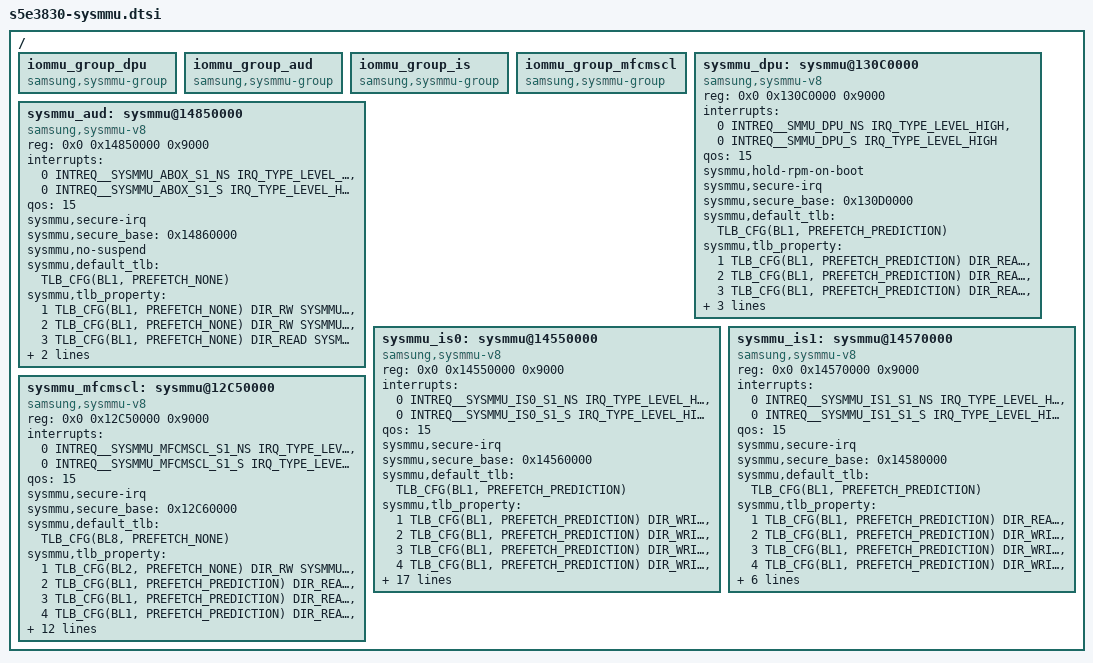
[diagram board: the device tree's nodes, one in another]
/*
 * SAMSUNG S5E3830 SoC device tree source
 *
 * Copyright (c) 2022 Samsung Electronics Co., Ltd.
 *             http://www.samsung.com
 *
 * SAMSUNG S5E3830 SoC device nodes are listed in this file.
 * S5E3830 based board files can include this file and provide
 * values for board specfic bindings.
 *
 * This program is free software; you can redistribute it and/or modify
 * it under the terms of the GNU General Public License version 2 as
 * published by the Free Software Foundation.
 */

#include <dt-bindings/interrupt-controller/arm-gic.h>
#include <dt-bindings/soc/samsung,sysmmu-v8.h>

/ {
	iommu_group_dpu: iommu_group_dpu {
		compatible = "samsung,sysmmu-group";
	};

	iommu_group_aud: iommu_group_aud {
		compatible = "samsung,sysmmu-group";
	};

	iommu_group_is: iommu_group_is {
		compatible = "samsung,sysmmu-group";
	};

	iommu_group_mfcmscl: iommu_group_mfcmscl {
		compatible = "samsung,sysmmu-group";
	};

	sysmmu_dpu: sysmmu@130C0000 {
		compatible = "samsung,sysmmu-v8";
		reg = <0x0 0x130C0000 0x9000>;
		interrupts = <0 INTREQ__SMMU_DPU_NS IRQ_TYPE_LEVEL_HIGH>,
			     <0 INTREQ__SMMU_DPU_S  IRQ_TYPE_LEVEL_HIGH>;
		qos = <15>;

		sysmmu,hold-rpm-on-boot;
		sysmmu,secure-irq;
		sysmmu,secure_base = <0x130D0000>;
		sysmmu,default_tlb = <TLB_CFG(BL1, PREFETCH_PREDICTION)>;
		sysmmu,tlb_property =
			<1 TLB_CFG(BL1, PREFETCH_PREDICTION) DIR_READ SYSMMU_ID_MASK(0x2, 0xF)>,
			<2 TLB_CFG(BL1, PREFETCH_PREDICTION) DIR_READ SYSMMU_ID_MASK(0x4, 0xF)>,
			<3 TLB_CFG(BL1, PREFETCH_PREDICTION) DIR_READ SYSMMU_ID_MASK(0x6, 0xF)>,
			<4 TLB_CFG(BL1, PREFETCH_PREDICTION) DIR_READ SYSMMU_ID_MASK(0x8, 0xF)>;
		port-name = "DPU";
		#iommu-cells = <0>;
		power-domains = <&pd_dpu>;
	};

	sysmmu_aud: sysmmu@14850000 {
		compatible = "samsung,sysmmu-v8";
		reg = <0x0 0x14850000 0x9000>;
		interrupts = <0 INTREQ__SYSMMU_ABOX_S1_NS IRQ_TYPE_LEVEL_HIGH>,
			     <0 INTREQ__SYSMMU_ABOX_S1_S  IRQ_TYPE_LEVEL_HIGH>;
		qos = <15>;

		sysmmu,secure-irq;
		sysmmu,secure_base = <0x14860000>;
		sysmmu,no-suspend;
		sysmmu,default_tlb = <TLB_CFG(BL1, PREFETCH_NONE)>;
		sysmmu,tlb_property =
			<1 TLB_CFG(BL1, PREFETCH_NONE) DIR_RW SYSMMU_ID_MASK(0x5, 0xF)>,
			<2 TLB_CFG(BL1, PREFETCH_NONE) DIR_RW SYSMMU_ID_MASK(0x0, 0x3)>,
			<3 TLB_CFG(BL1, PREFETCH_NONE) DIR_READ SYSMMU_ID_MASK(0x3, 0x3)>;
		port-name = "ABOX";
		#iommu-cells = <0>;
		power-domains = <&pd_aud>;
	};

	sysmmu_is0: sysmmu@14550000 {
		compatible = "samsung,sysmmu-v8";
		reg = <0x0 0x14550000 0x9000>;
		interrupts = <0 INTREQ__SYSMMU_IS0_S1_NS IRQ_TYPE_LEVEL_HIGH>,
			     <0 INTREQ__SYSMMU_IS0_S1_S  IRQ_TYPE_LEVEL_HIGH>;
		qos = <15>;

		sysmmu,secure-irq;
		sysmmu,secure_base = <0x14560000>;
		sysmmu,default_tlb = <TLB_CFG(BL1, PREFETCH_PREDICTION)>;
		sysmmu,tlb_property =
			<1 TLB_CFG(BL1, PREFETCH_PREDICTION) DIR_WRITE SYSMMU_ID_MASK(0x2, 0x1F)>,
			<2 TLB_CFG(BL1, PREFETCH_PREDICTION) DIR_WRITE SYSMMU_ID_MASK(0x4, 0x1F)>,
			<3 TLB_CFG(BL1, PREFETCH_PREDICTION) DIR_WRITE SYSMMU_ID_MASK(0x6, 0x1F)>,
			<4 TLB_CFG(BL1, PREFETCH_PREDICTION) DIR_WRITE SYSMMU_ID_MASK(0x8, 0x1F)>,
			<5 TLB_CFG(BL1, PREFETCH_PREDICTION) DIR_WRITE SYSMMU_ID_MASK(0xA, 0x1F)>,
			<6 TLB_CFG(BL1, PREFETCH_PREDICTION) DIR_WRITE SYSMMU_ID_MASK(0xC, 0x1F)>,
			<7 TLB_CFG(BL1, PREFETCH_PREDICTION) DIR_WRITE SYSMMU_ID_MASK(0xE, 0x1F)>,
			<8 TLB_CFG(BL1, PREFETCH_PREDICTION) DIR_READ SYSMMU_ID_MASK(0x1, 0x1F)>,
			<9 TLB_CFG(BL1, PREFETCH_PREDICTION) DIR_READ SYSMMU_ID_MASK(0x11, 0x1F)>,
			<10 TLB_CFG(BL1, PREFETCH_PREDICTION) DIR_WRITE SYSMMU_ID_MASK(0x1, 0x1F)>,
			<11 TLB_CFG(BL1, PREFETCH_PREDICTION) DIR_WRITE SYSMMU_ID_MASK(0x3, 0x1F)>,
			<12 TLB_CFG(BL1, PREFETCH_PREDICTION) DIR_WRITE SYSMMU_ID_MASK(0x5, 0x1F)>,
			<13 TLB_CFG(BL1, PREFETCH_PREDICTION) DIR_WRITE SYSMMU_ID_MASK(0x7, 0x1F)>,
			<14 TLB_CFG(BL1, PREFETCH_PREDICTION) DIR_WRITE SYSMMU_ID_MASK(0x9, 0x1F)>,
			<15 TLB_CFG(BL1, PREFETCH_PREDICTION) DIR_WRITE SYSMMU_ID_MASK(0x11, 0x1F)>,
			<16 TLB_CFG(BL1, PREFETCH_PREDICTION) DIR_WRITE SYSMMU_ID_MASK(0x13, 0x1F)>,
			<17 TLB_CFG(BL1, PREFETCH_PREDICTION) DIR_WRITE SYSMMU_ID_MASK(0x15, 0x1F)>,
			<18 TLB_CFG(BL1, PREFETCH_PREDICTION) DIR_WRITE SYSMMU_ID_MASK(0x17, 0x1F)>,
			<19 TLB_CFG(BL1, PREFETCH_PREDICTION) DIR_WRITE SYSMMU_ID_MASK(0x19, 0x1F)>;
		port-name = "CSISX2, IPP";
		#iommu-cells = <0>;
		power-domains = <&pd_csis>;
	};

	sysmmu_is1: sysmmu@14570000 {
		compatible = "samsung,sysmmu-v8";
		reg = <0x0 0x14570000 0x9000>;
		interrupts = <0 INTREQ__SYSMMU_IS1_S1_NS IRQ_TYPE_LEVEL_HIGH>,
			     <0 INTREQ__SYSMMU_IS1_S1_S  IRQ_TYPE_LEVEL_HIGH>;
		qos = <15>;

		sysmmu,secure-irq;
		sysmmu,secure_base = <0x14580000>;
		sysmmu,default_tlb = <TLB_CFG(BL1, PREFETCH_PREDICTION)>;
		sysmmu,tlb_property =
			<1 TLB_CFG(BL1, PREFETCH_PREDICTION) DIR_READ SYSMMU_ID_MASK(0x4, 0x3F)>,
			<2 TLB_CFG(BL1, PREFETCH_PREDICTION) DIR_WRITE SYSMMU_ID_MASK(0x4, 0x3F)>,
			<3 TLB_CFG(BL1, PREFETCH_PREDICTION) DIR_WRITE SYSMMU_ID_MASK(0x1, 0x3F)>,
			<4 TLB_CFG(BL1, PREFETCH_PREDICTION) DIR_WRITE SYSMMU_ID_MASK(0x5, 0x3F)>,
			<5 TLB_CFG(BL1, PREFETCH_PREDICTION) DIR_WRITE SYSMMU_ID_MASK(0x9, 0x3F)>,
			<6 TLB_CFG(BL1, PREFETCH_PREDICTION) DIR_RW SYSMMU_ID_MASK(0x3, 0x3)>,
			<7 TLB_CFG(BL4, PREFETCH_PREDICTION) DIR_WRITE SYSMMU_ID_MASK(0x2, 0x3)>,
			<8 TLB_CFG(BL1, PREFETCH_PREDICTION) DIR_WRITE SYSMMU_ID_MASK(0x2, 0x3)>;
		port-name = "ITP, MCSC, VRA, GDC";
		#iommu-cells = <0>;
		power-domains = <&pd_csis>;
	};

	sysmmu_mfcmscl: sysmmu@12C50000 {
		compatible = "samsung,sysmmu-v8";
		reg = <0x0 0x12C50000 0x9000>;
		interrupts = <0 INTREQ__SYSMMU_MFCMSCL_S1_NS IRQ_TYPE_LEVEL_HIGH>,
			     <0 INTREQ__SYSMMU_MFCMSCL_S1_S  IRQ_TYPE_LEVEL_HIGH>;
		qos = <15>;

		sysmmu,secure-irq;
		sysmmu,secure_base = <0x12C60000>;
		sysmmu,default_tlb = <TLB_CFG(BL8, PREFETCH_NONE)>;
		sysmmu,tlb_property =
			<1 TLB_CFG(BL2, PREFETCH_NONE) DIR_RW SYSMMU_ID_MASK(0x1, 0x3)>,
			<2 TLB_CFG(BL1, PREFETCH_PREDICTION) DIR_READ SYSMMU_ID_MASK(0x2, 0xF)>,
			<3 TLB_CFG(BL1, PREFETCH_PREDICTION) DIR_READ SYSMMU_ID_MASK(0x6, 0xF)>,
			<4 TLB_CFG(BL1, PREFETCH_PREDICTION) DIR_READ SYSMMU_ID_MASK(0xA, 0xF)>,
			<5 TLB_CFG(BL1, PREFETCH_PREDICTION) DIR_WRITE SYSMMU_ID_MASK(0x2, 0xF)>,
			<6 TLB_CFG(BL1, PREFETCH_PREDICTION) DIR_WRITE SYSMMU_ID_MASK(0x6, 0xF)>,
			<7 TLB_CFG(BL1, PREFETCH_PREDICTION) DIR_WRITE SYSMMU_ID_MASK(0xA, 0xF)>,
			<8 TLB_CFG(BL32, PREFETCH_PREDICTION) DIR_READ SYSMMU_ID_MASK(0x3, 0x3F)>,
			<9 TLB_CFG(BL32, PREFETCH_PREDICTION) DIR_READ SYSMMU_ID_MASK(0x7, 0x3F)>,
			<10 TLB_CFG(BL4, PREFETCH_PREDICTION) DIR_READ SYSMMU_ID_MASK(0xB, 0x3F)>,
			<11 TLB_CFG(BL4, PREFETCH_PREDICTION) DIR_READ SYSMMU_ID_MASK(0xF, 0x3F)>,
			<12 TLB_CFG(BL32, PREFETCH_PREDICTION) DIR_WRITE SYSMMU_ID_MASK(0x23, 0x3F)>,
			<13 TLB_CFG(BL4, PREFETCH_PREDICTION) DIR_WRITE SYSMMU_ID_MASK(0x27, 0x3F)>,
			<14 TLB_CFG(BL4, PREFETCH_PREDICTION) DIR_WRITE SYSMMU_ID_MASK(0x2B, 0x3F)>;
		port-name = "MFC, JPEG, MCSC, MSCL";
		#iommu-cells = <0>;
		power-domains = <&pd_mfcmscl>;
	};
};
